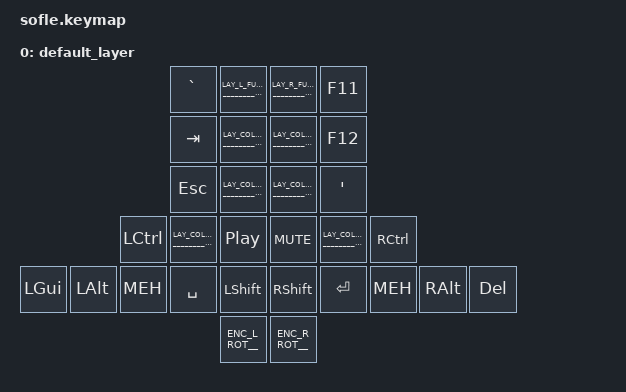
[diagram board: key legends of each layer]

#include <behaviors.dtsi>
#include <dt-bindings/zmk/keys.h>
#include <dt-bindings/zmk/bt.h>
#include <dt-bindings/zmk/rgb.h>
#include <dt-bindings/zmk/ext_power.h>

#include "../zmk-nodefree-config/helper.h"

/* source the main keymap */
#include "base.keymap"

ZMK_LAYER(default_layer,
//╭───────────┬────────┬────────┬─────────┬───────┬─────────────╮                                ╭──────────────┬───────┬─────────┬────────┬─────────┬──────────╮
   &kp GRAVE   _______________LAY_L_FUN_01_05_______________                                      _______________LAY_R_FUN_06_10_______________       &kp F11
//├───────────┼────────┼────────┼─────────┼───────┼─────────────┤                                ├──────────────┼───────┼─────────┼────────┼─────────┼──────────┤
   &kp TAB     _______________LAY_COLE_DH__LT_______________                                      _______________LAY_COLE_DH__RT_______________       &kp F12
//├───────────┼────────┼────────┼─────────┼───────┼─────────────┤                                ├──────────────┼───────┼─────────┼────────┼─────────┼──────────┤
   &kp ESC     _______________LAY_COLE_DH__LM_______________                                      _______________LAY_COLE_DH__RM_______________  &kp SQT
//├───────────┼────────┼────────┼─────────┼───────┼─────────────┼───────────────╮ ╭──────────────┼──────────────┼───────┼─────────┼────────┼─────────┼──────────┤
   &kp LCTRL   _______________LAY_COLE_DH__LB_______________     &kp C_PP          &kp C_MUTE     _______________LAY_COLE_DH__RB_______________  &kp RCTRL
//╰───────────┴────────┼────────┼─────────┼───────┼─────────────┼───────────────┤ ├──────────────┼──────────────┼───────┼─────────┼────────┼─────────┴──────────╯
                        &kp LGUI &kp LALT  &kp MEH &kp SPACE     &kp LSHFT         &kp RSHFT      &kp RET        &kp MEH &kp RALT  &kp DEL
//                     ╰────────┴─────────┴───────┴─────────────┴───────────────╯ ╰──────────────┴──────────────┴───────┴─────────┴────────╯
, __ENC_L_ROT__ __ENC_R_ROT__
)
